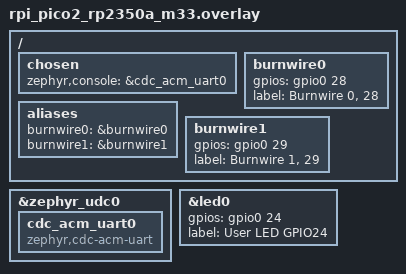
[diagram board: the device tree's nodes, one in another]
&zephyr_udc0 {
    cdc_acm_uart0: cdc_acm_uart0 {
        compatible = "zephyr,cdc-acm-uart";
    };
};

/ {
    chosen {
        zephyr,console = &cdc_acm_uart0;
    };

    aliases {
        burnwire0 = &burnwire0;
        burnwire1 = &burnwire1;
    };

    burnwire0: burnwire0 {
        gpios = <&gpio0 28 GPIO_ACTIVE_HIGH>;
        label = "Burnwire 0, 28";
    };

    burnwire1: burnwire1 {
        gpios = <&gpio0 29 GPIO_ACTIVE_HIGH>;
        label = "Burnwire 1, 29";
    };

};

/* Override the default LED definition to use GPIO 24 instead of GPIO 25 for PROVES FC board*/
&led0 {
    gpios = <&gpio0 24 GPIO_ACTIVE_HIGH>;
    label = "User LED GPIO24";
};
